# H6 register map
Vendor: Allwinner; Series: H6; File version: 0.1
CPU: CA53 0, little endian, MPU, no FPU, 0 interrupt priority bits
Registers are 32-bit, read-write, reset 0x0 unless marked. A register's access mark holds for its fields unless they carry their own. Offsets are from the block's base; [hi:lo] are bit positions; lines under a group give offsets from that group; {n}, {i} and the like mark numbered series.

## DMA
Base 0x03002000
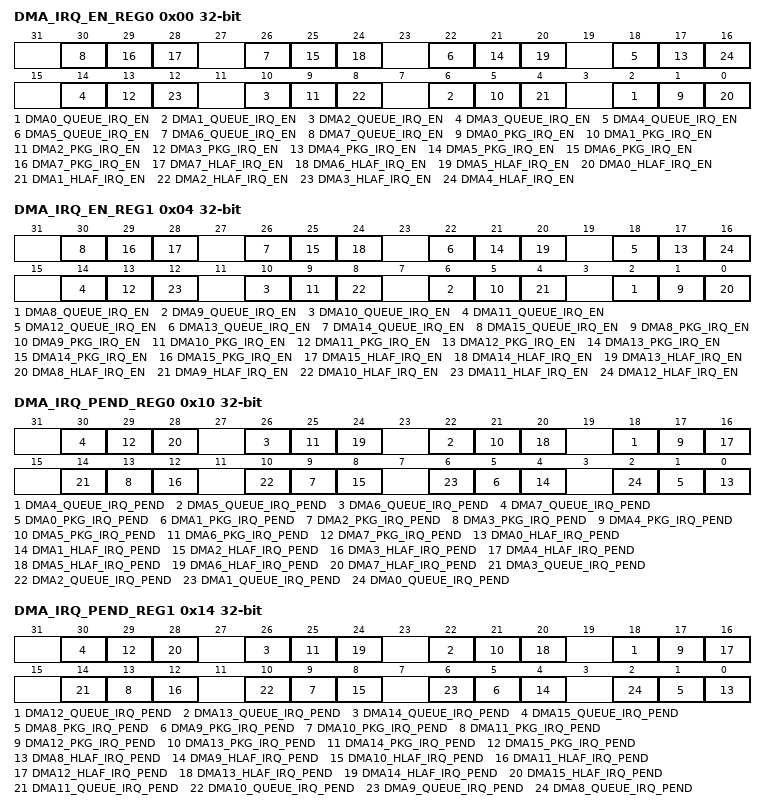
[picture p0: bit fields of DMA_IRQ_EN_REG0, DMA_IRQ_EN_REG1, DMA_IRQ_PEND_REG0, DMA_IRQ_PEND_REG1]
0x00 DMA_IRQ_EN_REG0 — DMA IRQ Enable Register 0
  [all] fields
    0=Disable; 1=Enable
  [4n+2] DMA{n}_QUEUE_IRQ_EN (n=0..7) — DMA {n} Queue End Transfer Interrupt Enable. 0: Disable 1: Enable
  [4n+1] DMA{n}_PKG_IRQ_EN (n=0..7) — DMA {n} Package End Transfer Interrupt Enable. 0: Disable 1: Enable
  [28] DMA7_HLAF_IRQ_EN — DMA 7 Half Package Transfer Interrupt Enable. 0: Disable 1: Enable
  [24] DMA6_HLAF_IRQ_EN — DMA 6 Half Package Transfer Interrupt Enable. 0: Disable 1: Enable
  [20] DMA5_HLAF_IRQ_EN — DMA 5 Half package Transfer Interrupt Enable. 0: Disable 1: Enable
  [4n] DMA{n}_HLAF_IRQ_EN (n=0..4) — DMA {n} Half Package Transfer Interrupt Enable. 0: Disable 1: Enable
0x04 DMA_IRQ_EN_REG1 — DMA IRQ Enable Register 1
  [all] fields
    0=Disable; 1=Enable
  [4n-30] DMA{n}_QUEUE_IRQ_EN (n=8..15) — DMA {n} Queue End Transfer Interrupt Enable. 0: Disable 1: Enable
  [4n-31] DMA{n}_PKG_IRQ_EN (n=8..15) — DMA {n} Package End Transfer Interrupt Enable. 0: Disable 1: Enable
  [28] DMA15_HLAF_IRQ_EN — DMA 15 Half Package Transfer Interrupt Enable. 0: Disable 1: Enable
  [24] DMA14_HLAF_IRQ_EN — DMA 14 Half Package Transfer Interrupt Enable. 0: Disable 1: Enable
  [20] DMA13_HLAF_IRQ_EN — DMA 13 Half package Transfer Interrupt Enable. 0: Disable 1: Enable
  [4n-32] DMA{n}_HLAF_IRQ_EN (n=8..12) — DMA {n} Half Package Transfer Interrupt Enable. 0: Disable 1: Enable
0x10 DMA_IRQ_PEND_REG0 — DMA IRQ Pending Register 0
  [4n+2] DMA{n}_QUEUE_IRQ_PEND write-1-clears (n=4..7) — DMA {n} Queue End Transfer Interrupt Pending. Setting 1 to the bit will clear it. 0: No effect 1: Pending
    0=No_effect; 1=Pending
  [4n+1] DMA{n}_PKG_IRQ_PEND write-1-clears (n=0..7) — DMA {n} Package End Transfer Interrupt Pending. Setting 1 to the bit will clear it. 0: No effect 1: Pending
    0=No_effect; 1=Pending
  [4n] DMA{n}_HLAF_IRQ_PEND write-1-clears (n=0..7) — DMA {n} Half Package Transfer Interrupt Pending. Setting 1 to the bit will clear it. 0: No effect 1: Pending
    0=No_effect; 1=Pending
  [14] DMA3_QUEUE_IRQ_PEND write-1-clears — DMA 3 Queue End Transfer Interrupt Pending. Setting 1 to the bit will clear it. 0: No effect, 1: Pending.
    0=No effect, 1: Pending
  [10] DMA2_QUEUE_IRQ_PEND write-1-clears — DMA 2 Queue End Transfer Interrupt Pending. Setting 1 to the bit will clear it. 0: No effect 1: Pending
    0=No_effect; 1=Pending
  [6] DMA1_QUEUE_IRQ_PEND write-1-clears — DMA 1 Queue End Transfer Interrupt Pending. Setting 1 to the bit will clear it. 0: No effect 1: Pending
    0=No_effect; 1=Pending
  [2] DMA0_QUEUE_IRQ_PEND write-1-clears — DMA 0 Queue End Transfer Interrupt Pending. Setting 1 to the bit will clear it. 0: No effect 1: Pending
    0=No_effect; 1=Pending
0x14 DMA_IRQ_PEND_REG1 — DMA IRQ Pending Register 1
  [4n-30] DMA{n}_QUEUE_IRQ_PEND write-1-clears (n=12..15) — DMA {n} Queue End Transfer Interrupt Pending. Setting 1 to the bit will clear it. 0: No effect 1: Pending
    0=No_effect; 1=Pending
  [4n-31] DMA{n}_PKG_IRQ_PEND write-1-clears (n=8..15) — DMA {n} Package End Transfer Interrupt Pending. Setting 1 to the bit will clear it. 0: No effect 1: Pending
    0=No_effect; 1=Pending
  [4n-32] DMA{n}_HLAF_IRQ_PEND write-1-clears (n=8..15) — DMA {n} Half Package Transfer Interrupt Pending. Setting 1 to the bit will clear it. 0: No effect 1: Pending
    0=No_effect; 1=Pending
  [14] DMA11_QUEUE_IRQ_PEND write-1-clears — DMA 11 Queue End Transfer Interrupt Pending. Setting 1 to the bit will clear it. 0: No effect, 1: Pending.
    0=No effect, 1: Pending
  [10] DMA10_QUEUE_IRQ_PEND write-1-clears — DMA 10 Queue End Transfer Interrupt Pending. Setting 1 to the bit will clear it. 0: No effect 1: Pending
    0=No_effect; 1=Pending
  [6] DMA9_QUEUE_IRQ_PEND write-1-clears — DMA 9 Queue End Transfer Interrupt Pending. Setting 1 to the bit will clear it. 0: No effect 1: Pending
    0=No_effect; 1=Pending
  [2] DMA8_QUEUE_IRQ_PEND write-1-clears — DMA 8 Queue End Transfer Interrupt Pending. Setting 1 to the bit will clear it. 0: No effect 1: Pending
    0=No_effect; 1=Pending
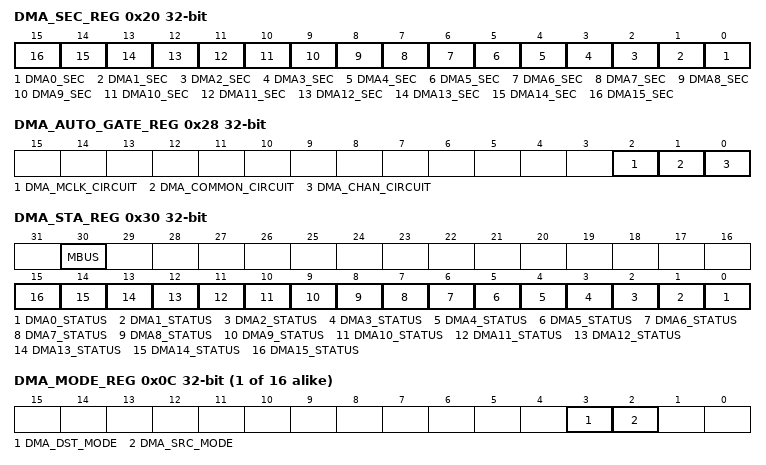
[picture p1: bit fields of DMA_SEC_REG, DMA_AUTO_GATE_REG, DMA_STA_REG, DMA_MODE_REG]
0x20 DMA_SEC_REG — DMA Security Register
  [all] fields
    0=Secure; 1=non_secure
  [n] DMA{n}_SEC (n=0..15) — DMA channel {n} security. 0: Secure 1: Non-secure.
0x28 DMA_AUTO_GATE_REG — DMA Auto Gating Register
  [all] fields
    0=Auto_gating_enable; 1=Auto_gating_disable
  [2] DMA_MCLK_CIRCUIT — DMA MCLK interface circuit auto gating bit. 0: Auto gating enable 1: Auto gating disable
  [1] DMA_COMMON_CIRCUIT — DMA common circuit auto gating bit. 0: Auto gating enable 1: Auto gating disable
  [0] DMA_CHAN_CIRCUIT — DMA channel circuit auto gating bit. 0: Auto gating enable 1: Auto gating disable
0x30 DMA_STA_REG — DMA Status Register
  [30] MBUS ro — FIFO Status 0: Empty 1: Not Empty
    0=Empty; 1=Not_Empty
  [n] DMA{n}_STATUS ro (n=0..15) — DMA Channel {n} Status. 0: Idle 1: Busy
    0=Idle; 1=Busy
{0x11C+0x40*i} _N[{i}] (i=0..15) group
  0x00 DMA_PARA_REG — DMA Channel Parameter Register(N=0~15)
    [7:0] WAIT_CYC ro — Wait Clock Cycles
  0x0C DMA_MODE_REG — DMA Mode Register(N=0~15)
    [3] DMA_DST_MODE — 0: Wait mode. 1: Handshake mode.
      0=Wait mode; 1=Handshake mode
    [2] DMA_SRC_MODE — 0: Wait mode. 1: Handshake mode.
      0=Wait mode; 1=Handshake mode
